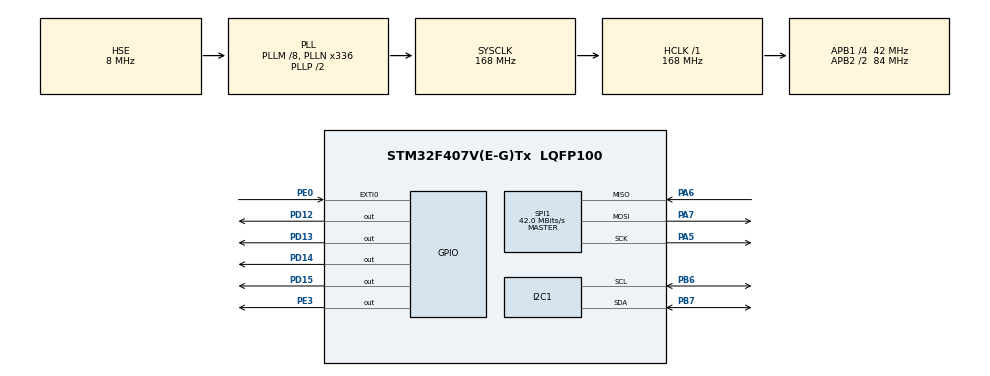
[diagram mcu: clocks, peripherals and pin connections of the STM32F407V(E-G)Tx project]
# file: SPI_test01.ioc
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Mcu.Family=STM32F4
Mcu.Name=STM32F407V(E-G)Tx
Mcu.Package=LQFP100
NVIC.EXTI0_IRQn=true\:0\:0\:false\:false\:true\:true\:true\:true
NVIC.PriorityGroup=NVIC_PRIORITYGROUP_0
PA5.Mode=Full_Duplex_Master
PA5.Signal=SPI1_SCK
PA6.Mode=Full_Duplex_Master
PA6.Signal=SPI1_MISO
PA7.Mode=Full_Duplex_Master
PA7.Signal=SPI1_MOSI
PB6.Mode=I2C
PB6.Signal=I2C1_SCL
PB7.Mode=I2C
PB7.Signal=I2C1_SDA
PD12.Signal=GPIO_Output
PD13.Signal=GPIO_Output
PD14.Signal=GPIO_Output
PD15.Signal=GPIO_Output
PE0.Signal=GPXTI0
PE3.PinState=GPIO_PIN_SET
PE3.Signal=GPIO_Output
PH0-OSC_IN.Mode=HSE-External-Oscillator
PH0-OSC_IN.Signal=RCC_OSC_IN
PH1-OSC_OUT.Mode=HSE-External-Oscillator
PH1-OSC_OUT.Signal=RCC_OSC_OUT
ProjectManager.HeapSize=0x200
ProjectManager.StackSize=0x400
ProjectManager.TargetToolchain=MDK-ARM V5.32
RCC.48MHZClocksFreq_Value=48000000
RCC.AHBFreq_Value=168000000
RCC.APB1CLKDivider=RCC_HCLK_DIV4
RCC.APB1Freq_Value=42000000
RCC.APB1TimFreq_Value=84000000
RCC.APB2CLKDivider=RCC_HCLK_DIV2
RCC.APB2Freq_Value=84000000
RCC.APB2TimFreq_Value=168000000
RCC.CortexFreq_Value=168000000
RCC.HCLKFreq_Value=168000000
RCC.HSE_VALUE=8000000
RCC.HSI_VALUE=16000000
RCC.LSE_VALUE=32768
RCC.PLLM=8
RCC.PLLN=336
RCC.PLLQ=7
RCC.PLLSourceVirtual=RCC_PLLSOURCE_HSE
RCC.SYSCLKFreq_VALUE=168000000
RCC.SYSCLKSource=RCC_SYSCLKSOURCE_PLLCLK
RCC.VCOOutputFreq_Value=336000000
SPI1.CalculateBaudRate=42.0 MBits/s
SPI1.Direction=SPI_DIRECTION_2LINES
SPI1.Mode=SPI_MODE_MASTER
SPI1.VirtualType=VM_MASTER
board=STM32F407G-DISC1

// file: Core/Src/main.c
/* USER CODE BEGIN Header */
/**
  ******************************************************************************
  * @file           : main.c
  * @brief          : Main program body
  ******************************************************************************
  * @attention
  *
  * Copyright (c) 2024 STMicroelectronics.
  * All rights reserved.
  *
  * This software is licensed under terms that can be found in the LICENSE file
  * in the root directory of this software component.
  * If no LICENSE file comes with this software, it is provided AS-IS.
  *
  ******************************************************************************
  */
/* USER CODE END Header */
#include "main.h"

/* USER CODE BEGIN Includes */
#include "stm32f4_discovery_accelerometer.h"

/* USER CODE END Includes */

I2C_HandleTypeDef hi2c1;

SPI_HandleTypeDef hspi1;

void SystemClock_Config(void);
static void MX_GPIO_Init(void);
static void MX_SPI1_Init(void);
static void MX_I2C1_Init(void);

/* USER CODE BEGIN 0 */
int16_t acceleroData[3];
/* USER CODE END 0 */

int main(void)
{

  /* MCU Configuration--------------------------------------------------------*/

  /* Reset of all peripherals, Initializes the Flash interface and the Systick. */
  HAL_Init();

  /* Configure the system clock */
  SystemClock_Config();

  /* Initialize all configured peripherals */
  MX_GPIO_Init();
  MX_SPI1_Init();
  MX_I2C1_Init();
  /* USER CODE BEGIN 2 */
  if (BSP_ACCELERO_Init() != ACCELERO_OK){
	while(1){
	HAL_GPIO_TogglePin(GPIOD,GPIO_PIN_12 | GPIO_PIN_13 | GPIO_PIN_14 | GPIO_PIN_15);
	HAL_Delay(200);
	}
	}
  /* USER CODE END 2 */

  /* Infinite loop */
  while (1)
  {
    BSP_ACCELERO_GetXYZ(acceleroData);
  }
}

void SystemClock_Config(void)
{
  RCC_OscInitTypeDef RCC_OscInitStruct = {0};
  RCC_ClkInitTypeDef RCC_ClkInitStruct = {0};

  /** Configure the main internal regulator output voltage
  */
  __HAL_RCC_PWR_CLK_ENABLE();
  __HAL_PWR_VOLTAGESCALING_CONFIG(PWR_REGULATOR_VOLTAGE_SCALE1);

  /** Initializes the RCC Oscillators according to the specified parameters
  * in the RCC_OscInitTypeDef structure.
  */
  RCC_OscInitStruct.OscillatorType = RCC_OSCILLATORTYPE_HSE;
  RCC_OscInitStruct.HSEState = RCC_HSE_ON;
  RCC_OscInitStruct.PLL.PLLState = RCC_PLL_ON;
  RCC_OscInitStruct.PLL.PLLSource = RCC_PLLSOURCE_HSE;
  RCC_OscInitStruct.PLL.PLLM = 8;
  RCC_OscInitStruct.PLL.PLLN = 336;
  RCC_OscInitStruct.PLL.PLLP = RCC_PLLP_DIV2;
  RCC_OscInitStruct.PLL.PLLQ = 7;
  if (HAL_RCC_OscConfig(&RCC_OscInitStruct) != HAL_OK)
  {
    Error_Handler();
  }

  /** Initializes the CPU, AHB and APB buses clocks
  */
  RCC_ClkInitStruct.ClockType = RCC_CLOCKTYPE_HCLK|RCC_CLOCKTYPE_SYSCLK
                              |RCC_CLOCKTYPE_PCLK1|RCC_CLOCKTYPE_PCLK2;
  RCC_ClkInitStruct.SYSCLKSource = RCC_SYSCLKSOURCE_PLLCLK;
  RCC_ClkInitStruct.AHBCLKDivider = RCC_SYSCLK_DIV1;
  RCC_ClkInitStruct.APB1CLKDivider = RCC_HCLK_DIV4;
  RCC_ClkInitStruct.APB2CLKDivider = RCC_HCLK_DIV2;

  if (HAL_RCC_ClockConfig(&RCC_ClkInitStruct, FLASH_LATENCY_5) != HAL_OK)
  {
    Error_Handler();
  }
}

static void MX_I2C1_Init(void)
{

  hi2c1.Instance = I2C1;
  hi2c1.Init.ClockSpeed = 100000;
  hi2c1.Init.DutyCycle = I2C_DUTYCYCLE_2;
  hi2c1.Init.OwnAddress1 = 0;
  hi2c1.Init.AddressingMode = I2C_ADDRESSINGMODE_7BIT;
  hi2c1.Init.DualAddressMode = I2C_DUALADDRESS_DISABLE;
  hi2c1.Init.OwnAddress2 = 0;
  hi2c1.Init.GeneralCallMode = I2C_GENERALCALL_DISABLE;
  hi2c1.Init.NoStretchMode = I2C_NOSTRETCH_DISABLE;
  if (HAL_I2C_Init(&hi2c1) != HAL_OK)
  {
    Error_Handler();
  }

}

static void MX_SPI1_Init(void)
{

  /* SPI1 parameter configuration*/
  hspi1.Instance = SPI1;
  hspi1.Init.Mode = SPI_MODE_MASTER;
  hspi1.Init.Direction = SPI_DIRECTION_2LINES;
  hspi1.Init.DataSize = SPI_DATASIZE_8BIT;
  hspi1.Init.CLKPolarity = SPI_POLARITY_LOW;
  hspi1.Init.CLKPhase = SPI_PHASE_1EDGE;
  hspi1.Init.NSS = SPI_NSS_SOFT;
  hspi1.Init.BaudRatePrescaler = SPI_BAUDRATEPRESCALER_2;
  hspi1.Init.FirstBit = SPI_FIRSTBIT_MSB;
  hspi1.Init.TIMode = SPI_TIMODE_DISABLE;
  hspi1.Init.CRCCalculation = SPI_CRCCALCULATION_DISABLE;
  hspi1.Init.CRCPolynomial = 10;
  if (HAL_SPI_Init(&hspi1) != HAL_OK)
  {
    Error_Handler();
  }

}

static void MX_GPIO_Init(void)
{
  GPIO_InitTypeDef GPIO_InitStruct = {0};

  /* GPIO Ports Clock Enable */
  __HAL_RCC_GPIOE_CLK_ENABLE();
  __HAL_RCC_GPIOH_CLK_ENABLE();
  __HAL_RCC_GPIOA_CLK_ENABLE();
  __HAL_RCC_GPIOD_CLK_ENABLE();
  __HAL_RCC_GPIOB_CLK_ENABLE();

  /*Configure GPIO pin Output Level */
  HAL_GPIO_WritePin(GPIOE, GPIO_PIN_3, GPIO_PIN_SET);

  /*Configure GPIO pin Output Level */
  HAL_GPIO_WritePin(GPIOD, GPIO_PIN_12|GPIO_PIN_13|GPIO_PIN_14|GPIO_PIN_15, GPIO_PIN_RESET);

  /*Configure GPIO pin : PE3 */
  GPIO_InitStruct.Pin = GPIO_PIN_3;
  GPIO_InitStruct.Mode = GPIO_MODE_OUTPUT_PP;
  GPIO_InitStruct.Pull = GPIO_NOPULL;
  GPIO_InitStruct.Speed = GPIO_SPEED_FREQ_LOW;
  HAL_GPIO_Init(GPIOE, &GPIO_InitStruct);

  /*Configure GPIO pins : PD12 PD13 PD14 PD15 */
  GPIO_InitStruct.Pin = GPIO_PIN_12|GPIO_PIN_13|GPIO_PIN_14|GPIO_PIN_15;
  GPIO_InitStruct.Mode = GPIO_MODE_OUTPUT_PP;
  GPIO_InitStruct.Pull = GPIO_NOPULL;
  GPIO_InitStruct.Speed = GPIO_SPEED_FREQ_LOW;
  HAL_GPIO_Init(GPIOD, &GPIO_InitStruct);

  /*Configure GPIO pin : PE0 */
  GPIO_InitStruct.Pin = GPIO_PIN_0;
  GPIO_InitStruct.Mode = GPIO_MODE_IT_RISING;
  GPIO_InitStruct.Pull = GPIO_NOPULL;
  HAL_GPIO_Init(GPIOE, &GPIO_InitStruct);

  /* EXTI interrupt init*/
  HAL_NVIC_SetPriority(EXTI0_IRQn, 0, 0);
  HAL_NVIC_EnableIRQ(EXTI0_IRQn);

}

void Error_Handler(void)
{
  __disable_irq();
  while (1)
  {
  }
}
